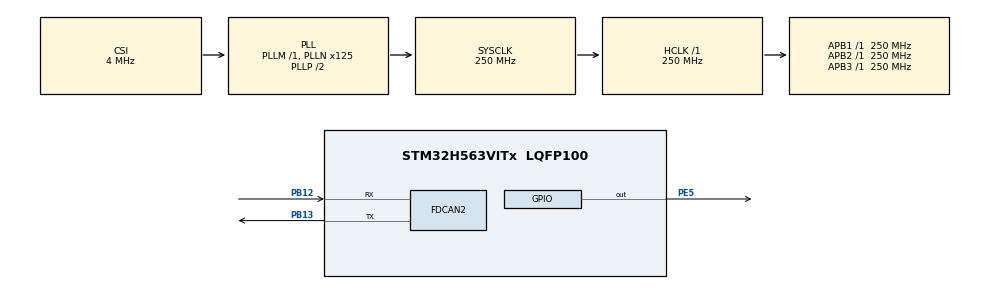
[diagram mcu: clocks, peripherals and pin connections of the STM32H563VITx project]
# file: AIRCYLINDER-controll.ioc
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BOOTPATH.BootPathName=LEGACY
BOOTPATH.UserSelectedBootPath=LEGACY
CORTEX_M33_NS.Number-Cortex_Memory_Protection_Unit_Region0_OTP_RO_AREAS_Settings=MPU_REGION_NUMBER0
CORTEX_M33_NS.default_mode_Activation=1
CORTEX_M33_NS.userName=CORTEX_M33
FDCAN2.CalculateBaudRateNominal=1000000
FDCAN2.CalculateTimeBitNominal=1000
FDCAN2.CalculateTimeQuantumNominal=40.0
FDCAN2.DataPrescaler=1
FDCAN2.DataTimeSeg1=20
FDCAN2.DataTimeSeg2=4
FDCAN2.FrameFormat=FDCAN_FRAME_FD_NO_BRS
FDCAN2.NominalPrescaler=10
FDCAN2.NominalTimeSeg1=20
FDCAN2.NominalTimeSeg2=4
FDCAN2.StdFiltersNbr=1
Mcu.Family=STM32H5
Mcu.Name=STM32H563VITx
Mcu.Package=LQFP100
NVIC.FDCAN2_IT0_IRQn=true\:0\:0\:false\:false\:true\:true\:true\:true
NVIC.FDCAN2_IT1_IRQn=true\:0\:0\:false\:false\:true\:true\:true\:true
NVIC.PriorityGroup=NVIC_PRIORITYGROUP_4
PB12.Mode=FDCAN_Activate
PB12.Signal=FDCAN2_RX
PB13.Mode=FDCAN_Activate
PB13.Signal=FDCAN2_TX
PE5.Signal=GPIO_Output
ProjectManager.HeapSize=0x200
ProjectManager.StackSize=0x400
ProjectManager.TargetToolchain=STM32CubeIDE
RCC.ADCFreq_Value=250000000
RCC.AHBFreq_Value=250000000
RCC.APB1Freq_Value=250000000
RCC.APB1TimFreq_Value=250000000
RCC.APB2Freq_Value=250000000
RCC.APB2TimFreq_Value=250000000
RCC.APB3Freq_Value=250000000
RCC.CSI_VALUE=4000000
RCC.CortexFreq_Value=250000000
RCC.EPOD_VALUE=4000000
RCC.FDCANClockSelection=RCC_FDCANCLKSOURCE_PLL1Q
RCC.HCLKFreq_Value=250000000
RCC.HSE_VALUE=25000000
RCC.HSI48_VALUE=48000000
RCC.HSI_VALUE=64000000
RCC.LSE_VALUE=32768
RCC.LSIRC_VALUE=32000
RCC.PLL2FRACN=0
RCC.PLL3FRACN=0
RCC.PLLFRACN=0
RCC.PLLN=125
RCC.SYSCLKFreq_VALUE=250000000
RCC.SYSCLKSource=RCC_SYSCLKSOURCE_PLLCLK
RCC.USBFreq_Value=48000000
RCC.VCOOutputFreq_Value=500000000
VP_BOOTPATH_VS_BOOTPATH.Mode=BP_Activate
VP_CORTEX_M33_NS_VS_Hclk.Mode=Hclk_Mode
VP_ICACHE_VS_ICACHE.Mode=DirectMappedCache
VP_MEMORYMAP_VS_MEMORYMAP.Mode=CurAppReg
VP_PWR_VS_LPOM.Mode=PowerOptimisation
VP_PWR_VS_SECSignals.Mode=Security/Privilege
board=custom

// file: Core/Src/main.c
/* USER CODE BEGIN Header */
/**
 ******************************************************************************
 * @file           : main.c
 * @brief          : Main program body
 ******************************************************************************
 * @attention
 *
 * Copyright (c) 2026 STMicroelectronics.
 * All rights reserved.
 *
 * This software is licensed under terms that can be found in the LICENSE file
 * in the root directory of this software component.
 * If no LICENSE file comes with this software, it is provided AS-IS.
 *
 ******************************************************************************
 */
/* USER CODE END Header */
#include "main.h"

/* USER CODE BEGIN PTD */
typedef struct {
	uint8_t cross :1;
	uint8_t circle :1;
	uint8_t triangle :1;
	uint8_t square :1;

	uint8_t l1 :1;
	uint8_t r1 :1;

	uint8_t share :1;
	uint8_t options :1;
	uint8_t ps :1;
	uint8_t :1; //dummy

	uint8_t l_stick_button :1;
	uint8_t r_stick_button :1;

	uint8_t up :1;
	uint8_t down :1;
	uint8_t left :1;
	uint8_t right :1;

	int8_t l_stick_x;
	int8_t l_stick_y;

	int8_t r_stick_x;
	int8_t r_stick_y;

	int8_t l2;
	int8_t r2;
} DS4_Controller_Typedef;
/* USER CODE END PTD */

FDCAN_HandleTypeDef hfdcan2;

/* USER CODE BEGIN PV */
FDCAN_RxHeaderTypeDef RxHeader;

// DualShock用構造体
DS4_Controller_Typedef DS4;
/* USER CODE END PV */

void SystemClock_Config(void);
static void MPU_Config(void);
static void MX_GPIO_Init(void);
static void MX_ICACHE_Init(void);
static void MX_FDCAN2_Init(void);
/* USER CODE BEGIN PFP */
void HAL_FDCAN_RxFifo0Callback(FDCAN_HandleTypeDef *hfdcan, uint32_t RxFifo0ITs) {
	/*if(hfdcan == &hfdcan1) {
	 // TODO: FDCAN1の受信
	 } else */if (hfdcan == &hfdcan2) {
		if ((RxFifo0ITs & FDCAN_IT_RX_FIFO0_NEW_MESSAGE) != RESET) {
			// Retrieve Rx messages from RX FIFO0
			if (HAL_FDCAN_GetRxMessage(hfdcan, FDCAN_RX_FIFO0, &RxHeader,
					(uint8_t*) &DS4) != HAL_OK) {
				Error_Handler();
			}
		}
	} /* else {
	 // TODO: 例外処理
	 }*/
}
/* USER CODE END PFP */

int main(void) {

	/* MCU Configuration--------------------------------------------------------*/

	/* MPU Configuration--------------------------------------------------------*/
	MPU_Config();

	/* Reset of all peripherals, Initializes the Flash interface and the Systick. */
	HAL_Init();

	/* Configure the system clock */
	SystemClock_Config();

	/* Initialize all configured peripherals */
	MX_GPIO_Init();
	MX_ICACHE_Init();
	MX_FDCAN2_Init();
	/* USER CODE BEGIN 2 */
	FDCAN_FilterTypeDef sFilterConfig;
	// Configure Rx filter
	sFilterConfig.IdType = FDCAN_STANDARD_ID;
	sFilterConfig.FilterIndex = 0;
	sFilterConfig.FilterType = FDCAN_FILTER_MASK;
	sFilterConfig.FilterConfig = FDCAN_FILTER_TO_RXFIFO0;
	sFilterConfig.FilterID1 = 0x000;
	sFilterConfig.FilterID2 = 0x000;
	if (HAL_FDCAN_ConfigFilter(&hfdcan2, &sFilterConfig) != HAL_OK) {
		Error_Handler();
	}
	if (HAL_FDCAN_ConfigGlobalFilter(&hfdcan2, FDCAN_REJECT, FDCAN_REJECT,
	FDCAN_REJECT_REMOTE, FDCAN_REJECT_REMOTE)) {
		Error_Handler();
	}
	// Enable Rx CallBack
	if (HAL_FDCAN_ActivateNotification(&hfdcan2, FDCAN_IT_RX_FIFO0_NEW_MESSAGE,
			0) != HAL_OK) {
		Error_Handler();
	}
	// Start the FDCAN module
	if (HAL_FDCAN_Start(&hfdcan2) != HAL_OK) {
		Error_Handler();
	}
	/* USER CODE END 2 */

	/* Infinite loop */
	while (1) {

		/* USER CODE BEGIN 3 */
		// ンダード エアシリンダー
		if (DS4.r1 == 1) {
			// シリンダーを出す
			HAL_GPIO_WritePin(GPIOE, GPIO_5, GPIO_PIN_RESET);
		} else if (DS4.r1 == 0) {
			// シリンダーを引っ込める
			HAL_GPIO_WritePin(GPIOE, GPIO_5, GPIO_PIN_RESET);
		}
	}
	/* USER CODE END 3 */
}

void SystemClock_Config(void) {
	RCC_OscInitTypeDef RCC_OscInitStruct = { 0 };
	RCC_ClkInitTypeDef RCC_ClkInitStruct = { 0 };

	/** Configure the main internal regulator output voltage
	 */
	__HAL_PWR_VOLTAGESCALING_CONFIG(PWR_REGULATOR_VOLTAGE_SCALE0);

	while (!__HAL_PWR_GET_FLAG(PWR_FLAG_VOSRDY)) {
	}

	/** Initializes the RCC Oscillators according to the specified parameters
	 * in the RCC_OscInitTypeDef structure.
	 */
	RCC_OscInitStruct.OscillatorType = RCC_OSCILLATORTYPE_CSI;
	RCC_OscInitStruct.CSIState = RCC_CSI_ON;
	RCC_OscInitStruct.CSICalibrationValue = RCC_CSICALIBRATION_DEFAULT;
	RCC_OscInitStruct.PLL.PLLState = RCC_PLL_ON;
	RCC_OscInitStruct.PLL.PLLSource = RCC_PLL1_SOURCE_CSI;
	RCC_OscInitStruct.PLL.PLLM = 1;
	RCC_OscInitStruct.PLL.PLLN = 125;
	RCC_OscInitStruct.PLL.PLLP = 2;
	RCC_OscInitStruct.PLL.PLLQ = 2;
	RCC_OscInitStruct.PLL.PLLR = 2;
	RCC_OscInitStruct.PLL.PLLRGE = RCC_PLL1_VCIRANGE_2;
	RCC_OscInitStruct.PLL.PLLVCOSEL = RCC_PLL1_VCORANGE_WIDE;
	RCC_OscInitStruct.PLL.PLLFRACN = 0;
	if (HAL_RCC_OscConfig(&RCC_OscInitStruct) != HAL_OK) {
		Error_Handler();
	}

	/** Initializes the CPU, AHB and APB buses clocks
	 */
	RCC_ClkInitStruct.ClockType = RCC_CLOCKTYPE_HCLK | RCC_CLOCKTYPE_SYSCLK
			| RCC_CLOCKTYPE_PCLK1 | RCC_CLOCKTYPE_PCLK2 | RCC_CLOCKTYPE_PCLK3;
	RCC_ClkInitStruct.SYSCLKSource = RCC_SYSCLKSOURCE_PLLCLK;
	RCC_ClkInitStruct.AHBCLKDivider = RCC_SYSCLK_DIV1;
	RCC_ClkInitStruct.APB1CLKDivider = RCC_HCLK_DIV1;
	RCC_ClkInitStruct.APB2CLKDivider = RCC_HCLK_DIV1;
	RCC_ClkInitStruct.APB3CLKDivider = RCC_HCLK_DIV1;

	if (HAL_RCC_ClockConfig(&RCC_ClkInitStruct, FLASH_LATENCY_5) != HAL_OK) {
		Error_Handler();
	}

	/** Configure the programming delay
	 */
	__HAL_FLASH_SET_PROGRAM_DELAY(FLASH_PROGRAMMING_DELAY_2);
}

static void MX_FDCAN2_Init(void) {

	hfdcan2.Instance = FDCAN2;
	hfdcan2.Init.ClockDivider = FDCAN_CLOCK_DIV1;
	hfdcan2.Init.FrameFormat = FDCAN_FRAME_FD_NO_BRS;
	hfdcan2.Init.Mode = FDCAN_MODE_NORMAL;
	hfdcan2.Init.AutoRetransmission = DISABLE;
	hfdcan2.Init.TransmitPause = DISABLE;
	hfdcan2.Init.ProtocolException = DISABLE;
	hfdcan2.Init.NominalPrescaler = 10;
	hfdcan2.Init.NominalSyncJumpWidth = 1;
	hfdcan2.Init.NominalTimeSeg1 = 20;
	hfdcan2.Init.NominalTimeSeg2 = 4;
	hfdcan2.Init.DataPrescaler = 1;
	hfdcan2.Init.DataSyncJumpWidth = 1;
	hfdcan2.Init.DataTimeSeg1 = 20;
	hfdcan2.Init.DataTimeSeg2 = 4;
	hfdcan2.Init.StdFiltersNbr = 1;
	hfdcan2.Init.ExtFiltersNbr = 0;
	hfdcan2.Init.TxFifoQueueMode = FDCAN_TX_FIFO_OPERATION;
	if (HAL_FDCAN_Init(&hfdcan2) != HAL_OK) {
		Error_Handler();
	}

}

static void MX_ICACHE_Init(void) {

	/** Enable instruction cache in 1-way (direct mapped cache)
	 */
	if (HAL_ICACHE_ConfigAssociativityMode(ICACHE_1WAY) != HAL_OK) {
		Error_Handler();
	}
	if (HAL_ICACHE_Enable() != HAL_OK) {
		Error_Handler();
	}

}

static void MX_GPIO_Init(void) {
	GPIO_InitTypeDef GPIO_InitStruct = { 0 };

	/* GPIO Ports Clock Enable */
	__HAL_RCC_GPIOE_CLK_ENABLE();
	__HAL_RCC_GPIOB_CLK_ENABLE();

	/*Configure GPIO pin Output Level */
	HAL_GPIO_WritePin(GPIOE, GPIO_PIN_5, GPIO_PIN_RESET);

	/*Configure GPIO pin : PE5 */
	GPIO_InitStruct.Pin = GPIO_PIN_5;
	GPIO_InitStruct.Mode = GPIO_MODE_OUTPUT_PP;
	GPIO_InitStruct.Pull = GPIO_NOPULL;
	GPIO_InitStruct.Speed = GPIO_SPEED_FREQ_LOW;
	HAL_GPIO_Init(GPIOE, &GPIO_InitStruct);

}

/* MPU Configuration */

void MPU_Config(void) {
	MPU_Region_InitTypeDef MPU_InitStruct = { 0 };
	MPU_Attributes_InitTypeDef MPU_AttributesInit = { 0 };

	/* Disables the MPU */
	HAL_MPU_Disable();

	/** Initializes and configures the Region 0 and the memory to be protected
	 */
	MPU_InitStruct.Enable = MPU_REGION_ENABLE;
	MPU_InitStruct.Number = MPU_REGION_NUMBER0;
	MPU_InitStruct.BaseAddress = 0x08FFF000;
	MPU_InitStruct.LimitAddress = 0x08FFFFFF;
	MPU_InitStruct.AttributesIndex = MPU_ATTRIBUTES_NUMBER0;
	MPU_InitStruct.AccessPermission = MPU_REGION_ALL_RO;
	MPU_InitStruct.DisableExec = MPU_INSTRUCTION_ACCESS_DISABLE;
	MPU_InitStruct.IsShareable = MPU_ACCESS_NOT_SHAREABLE;

	HAL_MPU_ConfigRegion(&MPU_InitStruct);

	/** Initializes and configures the Attribute 0 and the memory to be protected
	 */
	MPU_AttributesInit.Number = MPU_ATTRIBUTES_NUMBER0;
	MPU_AttributesInit.Attributes = INNER_OUTER(MPU_NOT_CACHEABLE);

	HAL_MPU_ConfigMemoryAttributes(&MPU_AttributesInit);
	/* Enables the MPU */
	HAL_MPU_Enable(MPU_PRIVILEGED_DEFAULT);

}

void Error_Handler(void) {
	__disable_irq();
	while (1) {
	}
}
